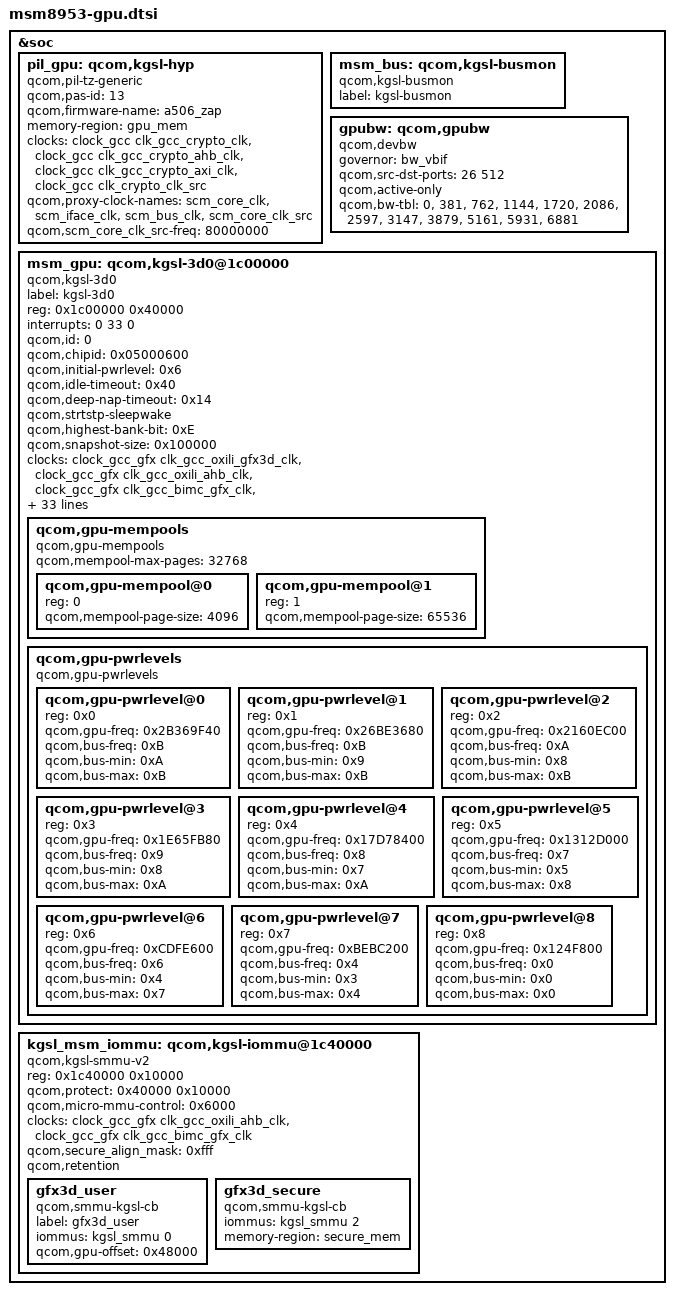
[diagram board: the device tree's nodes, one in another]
/* Copyright (c) 2018, The Linux Foundation. All rights reserved.
 * Copyright (c) 2018, Raphielscape LLC.
 *
 * This program is free software; you can redistribute it and/or modify
 * it under the terms of the GNU General Public License version 2 and
 * only version 2 as published by the Free Software Foundation.
 *
 * This program is distributed in the hope that it will be useful,
 * but WITHOUT ANY WARRANTY; without even the implied warranty of
 * MERCHANTABILITY or FITNESS FOR A PARTICULAR PURPOSE.  See the
 * GNU General Public License for more details.
 */

&soc {
	pil_gpu: qcom,kgsl-hyp {
		compatible = "qcom,pil-tz-generic";
		qcom,pas-id = <13>;
		qcom,firmware-name = "a506_zap";
		memory-region = <&gpu_mem>;
		clocks = <&clock_gcc clk_gcc_crypto_clk>,
		<&clock_gcc clk_gcc_crypto_ahb_clk>,
		<&clock_gcc clk_gcc_crypto_axi_clk>,
		<&clock_gcc clk_crypto_clk_src>;
		clock-names = "scm_core_clk", "scm_iface_clk",
				"scm_bus_clk", "scm_core_clk_src";
		qcom,proxy-clock-names = "scm_core_clk", "scm_iface_clk",
				"scm_bus_clk", "scm_core_clk_src";
		qcom,scm_core_clk_src-freq = <80000000>;
	};

	msm_bus: qcom,kgsl-busmon {
		label = "kgsl-busmon";
		compatible = "qcom,kgsl-busmon";
	};

	gpubw: qcom,gpubw {
		compatible = "qcom,devbw";
		governor = "bw_vbif";
		qcom,src-dst-ports = <26 512>;
		/*
		 * active-only flag is used while registering the bus
		 * governor.It helps release the bus vote when the CPU
		 * subsystem is inactive
		 */
		qcom,active-only;
		qcom,bw-tbl =
			<     0 /*  off     */ >,
			<   381 /*  100  MHz */ >,
			<   762 /*  200  MHz */ >,
			<  1144 /*  300  MHz */ >,
			<  1720 /*  451  MHz */ >,
			<  2086 /*  547  MHz */ >,
			<  2597 /*  681  MHz */ >,
			<  3147 /*  825  MHz */ >,
			<  3879 /*  1017 MHz */ >,
			<  5161 /*  1353 MHz */ >,
			<  5931 /*  1555 MHz */ >,
			<  6881 /*  1804 MHz */ >;
	};

	msm_gpu: qcom,kgsl-3d0@1c00000 {
		label = "kgsl-3d0";
		compatible = "qcom,kgsl-3d0", "qcom,kgsl-3d";
		status = "ok";
		reg = <0x1c00000 0x40000>;
		reg-names = "kgsl_3d0_reg_memory";
		interrupts = <0 33 0>;
		interrupt-names = "kgsl_3d0_irq";
		qcom,id = <0>;
		qcom,chipid = <0x05000600>;

		qcom,initial-pwrlevel = <0x6>;

		qcom,idle-timeout = <0x40>; //msecs
		/*
		 * Timeout to enter deeper power saving state
		 * from NAP.
		 */
		qcom,deep-nap-timeout = <0x14>; //msecs
		qcom,strtstp-sleepwake;

		qcom,highest-bank-bit = <0xE>;

		qcom,snapshot-size = <0x100000>; //bytes

		clocks = <&clock_gcc_gfx clk_gcc_oxili_gfx3d_clk>,
			<&clock_gcc_gfx clk_gcc_oxili_ahb_clk>,
			<&clock_gcc_gfx clk_gcc_bimc_gfx_clk>,
			<&clock_gcc_gfx clk_gcc_bimc_gpu_clk>,
			<&clock_gcc_gfx clk_gcc_oxili_timer_clk>,
			<&clock_gcc_gfx clk_gcc_oxili_aon_clk>;

		clock-names = "core_clk", "iface_clk",
			      "mem_iface_clk", "alt_mem_iface_clk",
			      "rbbmtimer_clk", "alwayson_clk";

		/* Bus Scale Settings */
		qcom,gpubw-dev = <&gpubw>;
		qcom,bus-control;
		qcom,bus-width = <32>;
		qcom,msm-bus,name = "grp3d";
		qcom,msm-bus,num-cases = <12>;
		qcom,msm-bus,num-paths = <1>;
		qcom,msm-bus,vectors-KBps =
			<26 512 0 0>,
			<26 512 0 400000>,     /*  1 bus=100  */
			<26 512 0 800000>,     /*  2 bus=200  */
			<26 512 0 1200000>,    /*  3 bus=300  */
			<26 512 0 1804000>,    /*  4 bus=451  */
			<26 512 0 2188000>,    /*  5 bus=547  */
			<26 512 0 2724000>,    /*  6 bus=681  */
			<26 512 0 3300000>,    /*  7 bus=825  */
			<26 512 0 4068000>,    /*  8 bus=1017 */
			<26 512 0 5412000>,    /*  9 bus=1353 */
			<26 512 0 6220000>,    /* 10 bus=1555 */
			<26 512 0 7216000>;    /* 11 bus=1804 */

		/* GDSC regulator names */
		regulator-names = "vddcx", "vdd";
		/* GDSC oxili regulators */
		vddcx-supply = <&gdsc_oxili_cx>;
		vdd-supply = <&gdsc_oxili_gx>;

		/* CPU latency parameter */
		qcom,pm-qos-active-latency = <0x206>;
		qcom,pm-qos-wakeup-latency = <0x206>;

		/* Quirks */
		qcom,gpu-quirk-two-pass-use-wfi;
		qcom,gpu-quirk-dp2clockgating-disable;

		/* Trace bus */
		coresight-id = <67>;
		coresight-name = "coresight-gfx";
		coresight-nr-inports = <0>;
		coresight-outports = <0>;
		coresight-child-list = <&funnel_mm>;
		coresight-child-ports = <6>;

		/* Enable context aware freq. scaling */
		qcom,enable-ca-jump;

		/* Enables the use of midframe sampling timer */
		qcom,enable-midframe-timer;

		/* Context aware jump busy penalty in us */
		qcom,ca-busy-penalty = <0x2EE0>;

		/* Context aware jump target power level */
		qcom,ca-target-pwrlevel = <4>;

		/* Enable gpu cooling device */
		#cooling-cells = <2>;

		/* GPU Mempools */
		qcom,gpu-mempools {
			#address-cells= <1>;
			#size-cells = <0>;
			compatible = "qcom,gpu-mempools";

			qcom,mempool-max-pages = <32768>;

			/* 4K Page Pool configuration */
			qcom,gpu-mempool@0 {
				reg = <0>;
				qcom,mempool-page-size = <4096>;
			};
			/* 64K Page Pool configuration */
			qcom,gpu-mempool@1 {
				reg = <1>;
				qcom,mempool-page-size  = <65536>;
			};
		};

		/* Power levels */
		qcom,gpu-pwrlevels {
			#address-cells = <1>;
			#size-cells = <0>;

			compatible = "qcom,gpu-pwrlevels";

		/* TURBO LD0 */
		qcom,gpu-pwrlevel@0 {
			reg = <0x0>;
			qcom,gpu-freq = <0x2B369F40>;
			qcom,bus-freq = <0xB>;
			qcom,bus-min = <0xA>;
			qcom,bus-max = <0xB>;
		};

		/* TURBO */
		qcom,gpu-pwrlevel@1 {
			reg = <0x1>;
			qcom,gpu-freq = <0x26BE3680>;
			qcom,bus-freq = <0xB>;
			qcom,bus-min = <0x9>;
			qcom,bus-max = <0xB>;
		};

		/* NOM+ */
		qcom,gpu-pwrlevel@2 {
			reg = <0x2>;
			qcom,gpu-freq = <0x2160EC00>;
			qcom,bus-freq = <0xA>;
			qcom,bus-min = <0x8>;
			qcom,bus-max = <0xB>;
		};

		/* NOM */
		qcom,gpu-pwrlevel@3 {
			reg = <0x3>;
			qcom,gpu-freq = <0x1E65FB80>;
			qcom,bus-freq = <0x9>;
			qcom,bus-min = <0x8>;
			qcom,bus-max = <0xA>;
		};

		/* SVS+ */
		qcom,gpu-pwrlevel@4 {
			reg = <0x4>;
			qcom,gpu-freq = <0x17D78400>;
			qcom,bus-freq = <0x8>;
			qcom,bus-min = <0x7>;
			qcom,bus-max = <0xA>;
		};

		/* SVS */
		qcom,gpu-pwrlevel@5 {
			reg = <0x5>;
			qcom,gpu-freq = <0x1312D000>;
			qcom,bus-freq = <0x7>;
			qcom,bus-min = <0x5>;
			qcom,bus-max = <0x8>;
		};

		/* Low SVS */
		qcom,gpu-pwrlevel@6 {
			reg = <0x6>;
			qcom,gpu-freq = <0xCDFE600>;
			qcom,bus-freq = <0x6>;
			qcom,bus-min = <0x4>;
			qcom,bus-max = <0x7>;
		};

		qcom,gpu-pwrlevel@7 {
			reg = <0x7>;
			qcom,gpu-freq = <0xBEBC200>;
			qcom,bus-freq = <0x4>;
			qcom,bus-min = <0x3>;
			qcom,bus-max = <0x4>;
		};

		/* XO */
		qcom,gpu-pwrlevel@8 {
			reg = <0x8>;
			qcom,gpu-freq = <0x124F800>;
			qcom,bus-freq = <0x0>;
			qcom,bus-min = <0x0>;
			qcom,bus-max = <0x0>;
			};
		};
	};

	kgsl_msm_iommu: qcom,kgsl-iommu@1c40000 {
		compatible = "qcom,kgsl-smmu-v2";

		reg = <0x1c40000 0x10000>;
		qcom,protect = <0x40000 0x10000>;
		qcom,micro-mmu-control = <0x6000>;

		clocks = <&clock_gcc_gfx clk_gcc_oxili_ahb_clk>,
			 <&clock_gcc_gfx clk_gcc_bimc_gfx_clk>;

		clock-names = "gpu_ahb_clk", "gcc_bimc_gfx_clk";

		qcom,secure_align_mask = <0xfff>;
		qcom,retention;
		gfx3d_user: gfx3d_user {
			compatible = "qcom,smmu-kgsl-cb";
			label = "gfx3d_user";
			iommus = <&kgsl_smmu 0>;
			qcom,gpu-offset = <0x48000>;
		};
		gfx3d_secure: gfx3d_secure {
			compatible = "qcom,smmu-kgsl-cb";
			iommus = <&kgsl_smmu 2>;
			memory-region = <&secure_mem>;
		};
	};
};
